# Cortex_M0 register map
Vendor: Arm Ltd.; Series: ARMv6-M; File version: 1.0.0
CPU: CM0 r0p0, little endian, no MPU, no FPU, 2 interrupt priority bits
Registers are 32-bit, read-only, reset 0x0 unless marked. A register's access mark holds for its fields unless they carry their own. Offsets are from the block's base; [hi:lo] are bit positions; {n}, {i} and the like mark numbered series.

## NVIC — Nested Vectored Interrupt Controller: enable, pending, active and priority registers for the external interrupts (IRQ0 = exception 16) and the software trigger register. Bit k of register n refers to IRQ 32n+k.
Base 0xE000E100
0x00 ISER0 rw — Interrupt Set-Enable Register n (IRQ 32n..32n+31): write 1 to enable an interrupt, 0 has no effect; reads the enable state.
  [31:0] SETENA — Bit k: write 1 to enable IRQ 32n+k; reads 1 if enabled. Writing 0 has no effect.
0x80 ICER0 rw — Interrupt Clear-Enable Register n (IRQ 32n..32n+31): write 1 to disable an interrupt, 0 has no effect; reads the enable state.
  [31:0] CLRENA — Bit k: write 1 to disable IRQ 32n+k; reads 1 if enabled. Writing 0 has no effect.
0x100 ISPR0 rw — Interrupt Set-Pending Register n (IRQ 32n..32n+31): write 1 to set an interrupt pending; reads the pending state.
  [31:0] SETPEND — Bit k: write 1 to set IRQ 32n+k pending; reads 1 if pending.
0x180 ICPR0 rw — Interrupt Clear-Pending Register n (IRQ 32n..32n+31): write 1 to clear a pending interrupt; reads the pending state.
  [31:0] CLRPEND — Bit k: write 1 to clear IRQ 32n+k pending; reads 1 if pending.
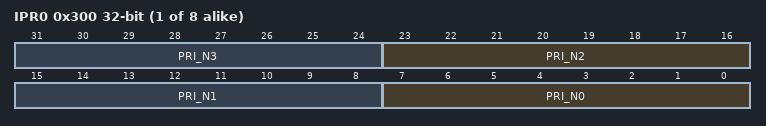
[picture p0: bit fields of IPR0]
{0x300+4i} IPR{i} (i=0..7) rw — Interrupt Priority Register n: one byte per interrupt, IRQ 4n+0 in bits [7:0] up to IRQ 4n+3 in [31:24]. Lower value = higher priority; only the top nvicPrioBits of each byte are implemented (ARMv6-M: 2, typical ARMv7-M: 3-4).
  [8n+7:8n] PRI_N{n} (n=0..3) — Priority of interrupt 4n+{n}. Only the top nvicPrioBits (implementation defined, 2 to 8) are implemented; the rest read as zero.

## DCB — Debug Control Block: halting debug control and status (DHCSR), core register access from the debugger (DCRSR/DCRDR), vector catch, the DebugMonitor exception and trace enable (DEMCR), and on ARMv8-M debug authentication and security control.
Base 0xE000EDF0
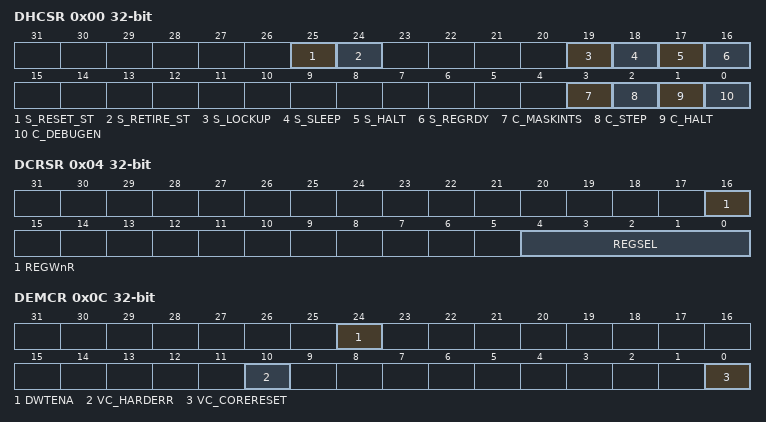
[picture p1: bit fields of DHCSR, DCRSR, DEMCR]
0x00 DHCSR rw — Debug Halting Control and Status Register: debugger enable, halt, step and interrupt masking (writes need 0xA05F in bits [31:16], DBGKEY), and read-only processor status (halted, sleeping, locked up, reset since last read) in the same upper bits.
  [25] S_RESET_ST ro — Sticky: the processor was reset since the last read of DHCSR. Cleared on read.
  [24] S_RETIRE_ST ro — Sticky: at least one instruction retired since the last read of DHCSR. Cleared on read.
  [19] S_LOCKUP ro — Processor is in lockup state - a fault occurred at priority -1 or in NMI/HardFault with no way to escalate; PC reads 0xFFFFFFFE. Read-only.
  [18] S_SLEEP ro — Processor is sleeping (WFI, WFE or sleep-on-exit). Read-only.
  [17] S_HALT ro — Processor is in Debug state (halted). Read-only.
  [16] S_REGRDY ro — Register transfer complete: a DCRSR read/write has finished and DCRDR is valid. Read-only.
  [3] C_MASKINTS — Mask PendSV, SysTick and IRQ (not NMI/faults) while stepping, so a step does not enter an interrupt handler. Change only while halted, together with C_HALT.
  [2] C_STEP — Single step: 1 = when leaving Debug state, execute one instruction and halt again.
  [1] C_HALT — Halt request: 1 = halt the processor (Debug state); 0 = run. Needs C_DEBUGEN = 1.
  [0] C_DEBUGEN — Halting debug enable. Set by the debugger; cannot be set by software. While 0 the other C_* bits are ignored and BKPT with no monitor escalates to HardFault.
0x04 DCRSR wo — Debug Core Register Selector Register: with the processor halted, selects a core register to transfer to or from DCRDR. Poll DHCSR.S_REGRDY for completion.
  [16] REGWnR — Direction: 0 = read the selected register into DCRDR, 1 = write DCRDR to the selected register.
  [4:0] REGSEL — Register to transfer: 0-12 R0-R12, 13 SP (current), 14 LR, 15 DebugReturnAddress (PC), 16 xPSR, 17 MSP, 18 PSP, 20 packed CONTROL[31:24] FAULTMASK[16] BASEPRI[8] PRIMASK[0], 33 FPSCR, 64-95 S0-S31; ARMv8-M: 24 MSP_NS, 25 PSP_NS, 26 MSP_S, 27 PSP_S, 28 MSPLIM_S, 29 PSPLIM_S, 30 MSPLIM_NS, 31 PSPLIM_NS, 34/35 packed CONTROL/masks _S/_NS.
0x08 DCRDR rw — Debug Core Register Data Register: data for DCRSR transfers. Also usable as a general debugger-to-target mailbox.
  [31:0] DBGTMP — Data read from, or to be written to, the register selected by DCRSR.
0x0C DEMCR rw — Debug Exception and Monitor Control Register: vector catch on reset and faults, DebugMonitor exception control, and TRCENA, the global enable for DWT, ITM, ETM and TPIU.
  [24] DWTENA — Enable the DWT (Data Watchpoint and Trace) unit. Must be set before programming DWT comparators.
  [10] VC_HARDERR — Vector catch on HardFault entry - with this set the core halts at the fault instead of running the HardFault handler.
  [0] VC_CORERESET — Vector catch on core reset: halt immediately after reset (the 'reset catch' debuggers use to stop at the first instruction). Needs C_DEBUGEN.

## Notices in the file
Copyright 2026 Arm Limited. Licensed under the Apache License, Version 2.0.
Copyright 2026 Arm Limited. Licensed under the Apache License, Version 2.0 (the "License");
you may not use this file except in compliance with the License. You may obtain a copy of the License at
https://www.apache.org/licenses/LICENSE-2.0
Unless required by applicable law or agreed to in writing, software
distributed under the License is distributed on an "AS IS" BASIS, WITHOUT WARRANTIES OR CONDITIONS OF ANY KIND,
either express or implied. See the License for the specific language governing permissions and limitations under the License.
